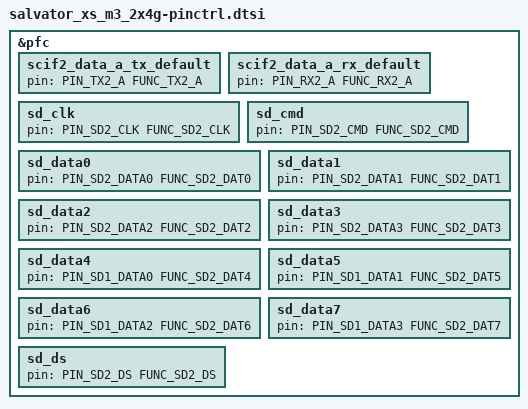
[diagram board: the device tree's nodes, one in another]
/*
 * Copyright (c) 2023 EPAM Systems
 *
 * SPDX-License-Identifier: Apache-2.0
 */

#include <zephyr/dt-bindings/pinctrl/renesas/pinctrl-r8a77960.h>

&pfc {
	scif2_data_a_tx_default: scif2_data_a_tx_default {
		pin = <PIN_TX2_A FUNC_TX2_A>;
	};

	scif2_data_a_rx_default: scif2_data_a_rx_default {
		pin = <PIN_RX2_A FUNC_RX2_A>;
	};

	sd_clk: sd_clk {
		pin = <PIN_SD2_CLK FUNC_SD2_CLK>;
	};

	sd_cmd: sd_cmd {
		pin = <PIN_SD2_CMD FUNC_SD2_CMD>;
	};

	sd_data0: sd_data0 {
		pin = <PIN_SD2_DATA0 FUNC_SD2_DAT0>;
	};

	sd_data1: sd_data1 {
		pin = <PIN_SD2_DATA1 FUNC_SD2_DAT1>;
	};

	sd_data2: sd_data2 {
		pin = <PIN_SD2_DATA2 FUNC_SD2_DAT2>;
	};

	sd_data3: sd_data3 {
		pin = <PIN_SD2_DATA3 FUNC_SD2_DAT3>;
	};

	sd_data4: sd_data4 {
		pin = <PIN_SD1_DATA0 FUNC_SD2_DAT4>;
	};

	sd_data5: sd_data5 {
		pin = <PIN_SD1_DATA1 FUNC_SD2_DAT5>;
	};

	sd_data6: sd_data6 {
		pin = <PIN_SD1_DATA2 FUNC_SD2_DAT6>;
	};

	sd_data7: sd_data7 {
		pin = <PIN_SD1_DATA3 FUNC_SD2_DAT7>;
	};

	sd_ds: sd_ds {
		pin = <PIN_SD2_DS FUNC_SD2_DS>;
	};
};
